# XMC1300 register map
Vendor: Infineon; File version: 1.2.2 (Reference Manual v1.2)
CPU: CM0 r0p0, little endian, no MPU, no FPU, 2 interrupt priority bits
Registers are 32-bit, read-write, reset 0x0 unless marked. A register's access mark holds for its fields unless they carry their own. Offsets are from the block's base; [hi:lo] are bit positions; {n}, {i} and the like mark numbered series.

## PRNG — PRNG Unit
Base 0x48020000
0x00 WORD 16-bit — PRNG Word Register
  [15:0] RDATA — Random Data
0x04 CHK 16-bit ro — PRNG Status Check Register
  [0] RDV — Random Data / Key Valid Flag
    0=New random data block is not yet ready to be read. In ) this flag is set to #0 while loading is in progress.; 1=Random data block is valid. In key loading mode this value indicates that the next partial key word can be written to PRNG_WORD.
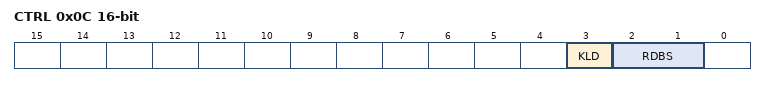
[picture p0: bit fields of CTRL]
0x0C CTRL 16-bit — PRNG Control Register
  [3] KLD — Key Load Operation Mode
    0=Streaming mode (default); 1=Key loading mode
  [2:1] RDBS — Random Data Block Size
    0=Reset state (no random data block size defined), value of PRNG_WORD is undefined; 1=8 bits in PRNG_WORD.RDATA[7:0]; 2=16 bits in PRNG_WORD.RDATA[15:0]

## USIC0 — Universal Serial Interface Controller 0
Base 0x48000008
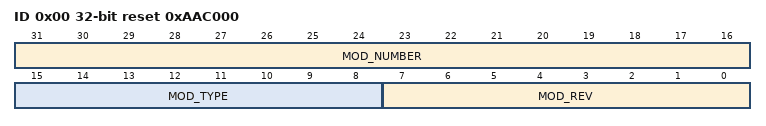
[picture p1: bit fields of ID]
0x00 ID ro reset 0xAAC000 (reset mask 0xFFFFFF00) — Module Identification Register
  [31:16] MOD_NUMBER — Module Number Value
  [15:8] MOD_TYPE — Module Type
  [7:0] MOD_REV — Module Revision Number

## SCU_GENERAL — System Control Unit
Base 0x40010000
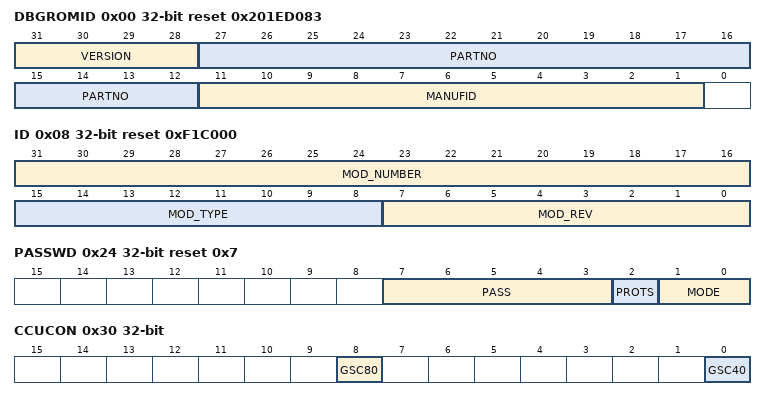
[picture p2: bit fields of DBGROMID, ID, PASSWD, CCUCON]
0x00 DBGROMID ro reset 0x201ED083 — Debug System ROM ID Register
  [31:28] VERSION — Product version
  [27:12] PARTNO — Part Number
  [11:1] MANUFID — Manufactory Identity
0x04 IDCHIP ro — Chip ID Register
  [31:0] IDCHIP — CHIP ID
0x08 ID ro reset 0xF1C000 (reset mask 0xFFFFFF00) — SCU Module ID Register
  [31:16] MOD_NUMBER — Module Number Value
  [15:8] MOD_TYPE — Module Type
  [7:0] MOD_REV — Module Revision Number
0x14 SSW0 — SSW Register 0
  [31:0] DAT — SSW Data
0x24 PASSWD access per field reset 0x7 — Password Register
  [7:3] PASS wo — Password Bits
    24=Enables writing of the bit field MODE; 19=Opens access to writing of all protected bits; 21=Closes access to writing of all protected bits
  [2] PROTS ro — Bit Protection Signal Status Bit
    0=Software is able to write to all protected bits; 1=Software is unable to write to any of the protected bits
  [1:0] MODE rw — Bit Protection Scheme Control Bits
    0=Scheme disabled - direct access to the protected bits is allowed; 3=Scheme enabled - the bit field PASS has to be written with the passwords to open and close the access to the protected bits. (Default)
0x30 CCUCON — CCU Control Register
  [8] GSC80 — Global Start Control CCU80
  [0] GSC40 — Global Start Control CCU40
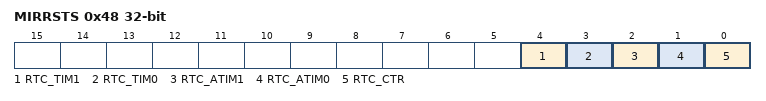
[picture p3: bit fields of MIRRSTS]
0x48 MIRRSTS ro — Mirror Update Status Register
  [4] RTC_TIM1 — RTC TIM1 Mirror Register Update Status
  [3] RTC_TIM0 — RTC TIM0 Mirror Register Update Status
  [2] RTC_ATIM1 — RTC ATIM1 Mirror Register Update Status
  [1] RTC_ATIM0 — RTC ATIM0 Mirror Register Update Status
  [0] RTC_CTR — RTC CTR Mirror Register Update Status
0x54 PMTSR — Parity Memory Test Select Register
  [0] MTENS — Parity Test Enable Control for 16kbytes SRAM
    0=standard operation; 1=generate an inverted parity bit during a write operation

## SCU_POWER — System Control Unit
Base 0x40010200
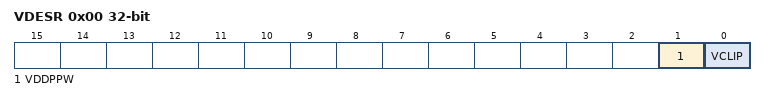
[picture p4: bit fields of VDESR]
0x00 VDESR ro — Voltage Detector Status Register
  [1] VDDPPW — VDDPPW Indication
    0=VDDP is above pre-warning threshold; 1=VDDP is below pre-warningthreshold
  [0] VCLIP — VCLIP Indication
    0=VCLIP is not active; 1=VCLIP is active

## SCU_CLK — System Control Unit
Base 0x40010300
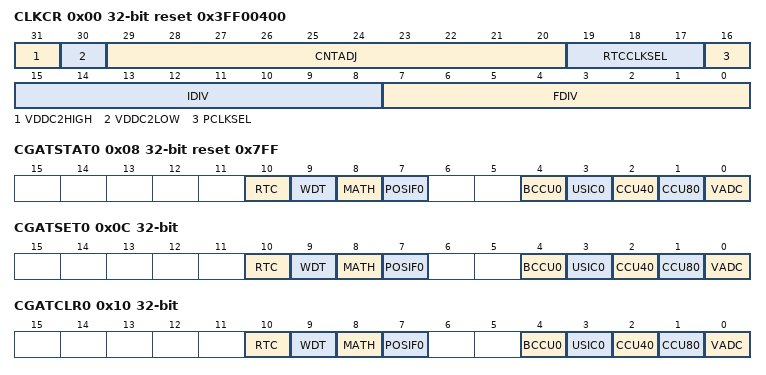
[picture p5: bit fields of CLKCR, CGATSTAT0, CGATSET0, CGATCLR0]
0x00 CLKCR access per field reset 0x3FF00400 — Clock Control Register
  [31] VDDC2HIGH ro — VDDC too high
    0=VDDC is not too high; 1=VDDC is too high
  [30] VDDC2LOW ro — VDDC too low
    0=VDDC is not too low and the fractional divider input clock is running at the targeted frequency; 1=VDDC is too low and the fractional divider input clock is not running at the targeted frequency
  [29:20] CNTADJ rw — Counter Adjustment
    {v}={v+1} clock cycles of the DCO1, 64MHz clock (v=0..4); 0x3FE=1023 clock cycles of the DCO1, 64MHz clock; 0x3FF=1024 clock cycles of the DCO1, 64MHz clock
  [19:17] RTCCLKSEL rw — RTC Clock Select
  [16] PCLKSEL rw — PCLK Clock Select
    0=PCLK = MCLK; 1=PCLK = 2 x MCLK
  [15:8] IDIV rw — Divider Selection
    0=Divider is bypassed; 1=1; MCLK = 32 MHz; 2=2; MCLK = 16 MHz; 3=3; MCLK = 10.67 MHz; 4=4; MCLK = 8 MHz; 254=254; MCLK = 126 kHz; 255=255; MCLK = 125.5 kHz
  [7:0] FDIV rw — Fractional Divider Selection
0x04 PWRSVCR — Power Save Control Register
  [0] FPD — Flash Power Down
    0=no effect; 1=Flash power down when entering power save mode. Upon wake-up, CPU is able to fetch code from flash.
0x08 CGATSTAT0 ro reset 0x7FF — Peripheral 0 Clock Gating Status
  [all] fields
    0=gating de-asserted; 1=gating asserted
  [10] RTC — RTC Gating Status
  [9] WDT — WDT Gating Status
  [8] MATH — MATH Gating Status
  [7] POSIF0 — POSIF0 Gating Status
  [4] BCCU0 — BCCU0 Gating Status
  [3] USIC0 — USIC0 Gating Status
  [2] CCU40 — CCU40 Gating Status
  [1] CCU80 — CCU80 Gating Status
  [0] VADC — VADC and SHS Gating Status
0x0C CGATSET0 wo — Peripheral 0 Clock Gating Set
  [all] fields
    0=no effect; 1=enable gating
  [10] RTC — RTC Gating Set
  [9] WDT — WDT Gating Set
  [8] MATH — MATH Gating Set
  [7] POSIF0 — POSIF0 Gating Set
  [4] BCCU0 — BCCU0 Gating Set
  [3] USIC0 — USIC0 Gating Set
  [2] CCU40 — CCU40 Gating Set
  [1] CCU80 — CCU80 Gating Set
  [0] VADC — VADC and SHS Gating Set
0x10 CGATCLR0 wo — Peripheral 0 Clock Gating Clear
  [10] RTC — RTC Gating Clear
    0=no effect; 1=disable gating
  [9] WDT — WDT Gating Clear
    0=no effect; 1=disable gating
  [8] MATH — MATH Gating Clear
    0=no effect; 1=disable gating
  [7] POSIF0 — POSIF0 Gating Clear
    0=no effect; 1=disable gating
  [4] BCCU0 — BCCU0 Gating Clear
    0=no effect; 1=disable gating
  [3] USIC0 — USIC0 Gating Clear
    0=no effect; 1=disable gating
  [2] CCU40 — CCU40 Gating Clear
    0=no effect; 1=disable gating
  [1] CCU80 — CCU80 Gating Clear
    0=no effect; 1=disble gating
  [0] VADC — VADC and SHS Gating Clear
    0=no effect; 1=disable gating
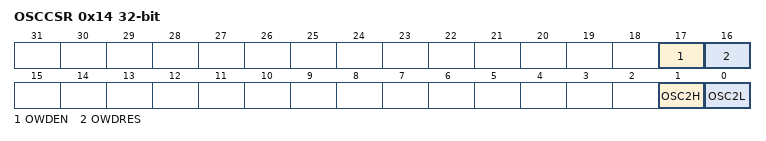
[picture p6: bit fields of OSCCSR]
0x14 OSCCSR access per field (reset mask 0xFFFFFFF0) — Oscillator Control and Status Register
  [17] OWDEN rw — Oscillator Watchdog Enable
    0=The Oscillator Watchdog is disabled; 1=The Oscillator Watchdog is enabled
  [16] OWDRES rw — Oscillator Watchdog Reset
    0=The Oscillator Watchdog is not cleared and remains active; 1=The Oscillator Watchdog is cleared and restarted. The OSC2L and OSC2H flag will be held in the last value until it is updated after 3 standby clock cycles.
  [1] OSC2H ro — Oscillator Valid High Status Bit
    0=The OSC frequency is usable; 1=The OSC frequency is not usable. Frequency is too high.
  [0] OSC2L ro — Oscillator Valid Low Status Bit
    0=The OSC frequency is usable; 1=The OSC frequency is not usable. Frequency is too low.
